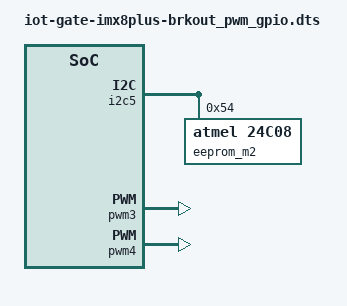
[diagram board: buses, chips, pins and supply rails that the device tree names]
// SPDX-License-Identifier: (GPL-2.0+ OR MIT)
/*
 * Copyright 2023 CompuLab Ltd
 */

#include "iot-gate-imx8plus.dts"

/*
 * IOT-GATE-IMX8PLUS with BRKOUT extension module in M.2 Expansion Connector
 * Example pionout:
 * ----+----+----------
 *  P1 | P5 | Function
 * ----+----+----------
 *  11 | 09 | PWM3_OUT
 *  09 | 07 | PWM4_OUT
 *  21 | 13 | GPIO5_IO10
 *  23 | 11 | GPIO5_IO11
 *  17 | 14 | GPIO5_IO12
 *  15 | 12 | GPIO5_IO13
 *  34 | 08 | I2C5_SDA
 *  36 | 10 | I2C5_SCL
 */

&gpio5 {
	pinctrl-names = "default";
	pinctrl-0 = <&pinctrl_gpio5>;
	status = "okay";
};

&ecspi2 {
	status = "disabled";
};

&i2c5 {
	status = "okay";

	eeprom_m2: eeprom-i2c5@54 {
		compatible = "atmel,24c08";
		pagesize = <16>;
		reg = <0x54>;
		status = "okay";
	};
};

&i2c6 {
	status = "disabled";
};

&pwm3 {
	pinctrl-names = "default";
	pinctrl-0 = <&pinctrl_pwm3>;
	status = "okay";
};

&pwm4 {
	pinctrl-names = "default";
	pinctrl-0 = <&pinctrl_pwm4>;
	status = "okay";
};

&usdhc2 {
	status = "disabled";
};

&iomuxc {
	pinctrl_gpio5: gpio5grp {
		fsl,pins = <
			MX8MP_IOMUXC_ECSPI2_SCLK__GPIO5_IO10			0x100 /* P5-13 */
			MX8MP_IOMUXC_ECSPI2_MOSI__GPIO5_IO11			0x100 /* P5-11 */
			MX8MP_IOMUXC_ECSPI2_MISO__GPIO5_IO12			0x100 /* P5-14 */
			MX8MP_IOMUXC_ECSPI2_SS0__GPIO5_IO13			0x100 /* P5-12 */
		>;
	};

	pinctrl_pwm3: pwm3grp {
		fsl,pins = <
			MX8MP_IOMUXC_SAI5_RXC__PWM3_OUT				0x116 /* P5-09 */
		>;
	};

	pinctrl_pwm4: pwm4grp {
		fsl,pins = <
			MX8MP_IOMUXC_SAI5_RXFS__PWM4_OUT			0x116 /* P5-11 */
		>;
	};
};
